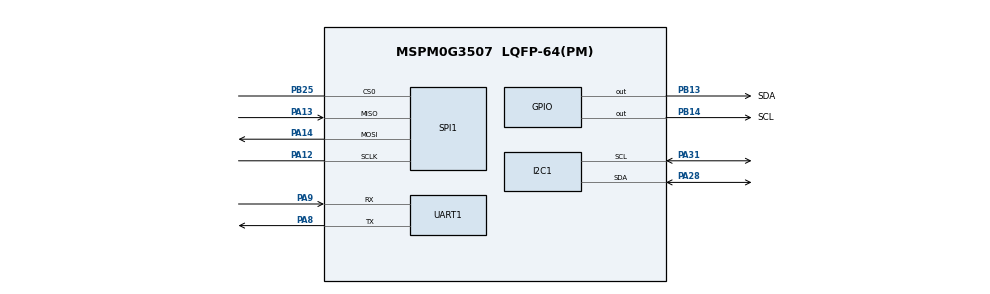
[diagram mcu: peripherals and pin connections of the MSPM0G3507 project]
/**
 * These arguments were used when this file was generated. They will be automatically applied on subsequent loads
 * via the GUI or CLI. Run CLI with '--help' for additional information on how to override these arguments.
 * @cliArgs --device "MSPM0G350X" --part "Default" --package "LQFP-64(PM)" --product "mspm0_sdk@2.11.00.07"
 * @v2CliArgs --device "MSPM0G3507" --package "LQFP-64(PM)" --product "mspm0_sdk@2.11.00.07"
 * @versions {"tool":"1.26.2+4477"}
 */

/**
 * Import the modules used in this configuration.
 */
const GPIO   = scripting.addModule("/ti/driverlib/GPIO", {}, false);
const GPIO1  = GPIO.addInstance();
const I2C    = scripting.addModule("/ti/driverlib/I2C", {}, false);
const I2C1   = I2C.addInstance();
const SPI    = scripting.addModule("/ti/driverlib/SPI", {}, false);
const SPI1   = SPI.addInstance();
const SYSCTL = scripting.addModule("/ti/driverlib/SYSCTL");
const TIMER  = scripting.addModule("/ti/driverlib/TIMER", {}, false);
const TIMER1 = TIMER.addInstance();
const UART   = scripting.addModule("/ti/driverlib/UART", {}, false);
const UART1  = UART.addInstance();

/**
 * Write custom configuration values to the imported modules.
 */
GPIO1.$name                         = "I2C_IMU";
GPIO1.associatedPins.create(2);
GPIO1.associatedPins[0].ioStructure = "SD";
GPIO1.associatedPins[0].$name       = "SCL";
GPIO1.associatedPins[0].pin.$assign = "PB14";
GPIO1.associatedPins[1].$name       = "SDA";
GPIO1.associatedPins[1].pin.$assign = "PB13";

const Board = scripting.addModule("/ti/driverlib/Board", {}, false);

I2C1.$name                             = "I2C_OLED";
I2C1.basicEnableController             = true;
I2C1.basicControllerStandardBusSpeed   = "Fast";
I2C1.peripheral.$assign                = "I2C0";
I2C1.peripheral.sdaPin.$assign         = "PA28";
I2C1.peripheral.sclPin.$assign         = "PA31";
I2C1.sdaPinConfig.$name                = "ti_driverlib_gpio_GPIOPinGeneric8";
I2C1.sdaPinConfig.hideOutputInversion  = scripting.forceWrite(false);
I2C1.sdaPinConfig.onlyInternalResistor = scripting.forceWrite(false);
I2C1.sdaPinConfig.passedPeripheralType = scripting.forceWrite("Digital");
I2C1.sclPinConfig.$name                = "ti_driverlib_gpio_GPIOPinGeneric9";
I2C1.sclPinConfig.hideOutputInversion  = scripting.forceWrite(false);
I2C1.sclPinConfig.onlyInternalResistor = scripting.forceWrite(false);
I2C1.sclPinConfig.passedPeripheralType = scripting.forceWrite("Digital");

SPI1.$name                              = "IMU";
SPI1.peripheral.$assign                 = "SPI0";
SPI1.peripheral.sclkPin.$assign         = "PA12";
SPI1.peripheral.mosiPin.$assign         = "PA14";
SPI1.peripheral.misoPin.$assign         = "PA13";
SPI1.peripheral.cs0Pin.$assign          = "PB25";
SPI1.sclkPinConfig.direction            = scripting.forceWrite("OUTPUT");
SPI1.sclkPinConfig.onlyInternalResistor = scripting.forceWrite(false);
SPI1.sclkPinConfig.passedPeripheralType = scripting.forceWrite("Digital");
SPI1.sclkPinConfig.$name                = "ti_driverlib_gpio_GPIOPinGeneric4";
SPI1.mosiPinConfig.direction            = scripting.forceWrite("OUTPUT");
SPI1.mosiPinConfig.hideOutputInversion  = scripting.forceWrite(false);
SPI1.mosiPinConfig.onlyInternalResistor = scripting.forceWrite(false);
SPI1.mosiPinConfig.passedPeripheralType = scripting.forceWrite("Digital");
SPI1.mosiPinConfig.$name                = "ti_driverlib_gpio_GPIOPinGeneric5";
SPI1.misoPinConfig.onlyInternalResistor = scripting.forceWrite(false);
SPI1.misoPinConfig.passedPeripheralType = scripting.forceWrite("Digital");
SPI1.misoPinConfig.$name                = "ti_driverlib_gpio_GPIOPinGeneric6";
SPI1.cs0PinConfig.direction             = scripting.forceWrite("OUTPUT");
SPI1.cs0PinConfig.hideOutputInversion   = scripting.forceWrite(false);
SPI1.cs0PinConfig.onlyInternalResistor  = scripting.forceWrite(false);
SPI1.cs0PinConfig.passedPeripheralType  = scripting.forceWrite("Digital");
SPI1.cs0PinConfig.$name                 = "ti_driverlib_gpio_GPIOPinGeneric7";

SYSCTL.forceDefaultClkConfig = true;

TIMER1.$name            = "TIMER_0";
TIMER1.timerClkPrescale = 32;
TIMER1.timerStartTimer  = true;
TIMER1.timerMode        = "PERIODIC_UP";

UART1.$name                            = "PIDHELPER";
UART1.targetBaudRate                   = 115200;
UART1.enabledInterrupts                = ["RX"];
UART1.peripheral.$assign               = "UART1";
UART1.peripheral.rxPin.$assign         = "PA9";
UART1.peripheral.txPin.$assign         = "PA8";
UART1.txPinConfig.direction            = scripting.forceWrite("OUTPUT");
UART1.txPinConfig.hideOutputInversion  = scripting.forceWrite(false);
UART1.txPinConfig.onlyInternalResistor = scripting.forceWrite(false);
UART1.txPinConfig.passedPeripheralType = scripting.forceWrite("Digital");
UART1.txPinConfig.$name                = "ti_driverlib_gpio_GPIOPinGeneric2";
UART1.rxPinConfig.hideOutputInversion  = scripting.forceWrite(false);
UART1.rxPinConfig.onlyInternalResistor = scripting.forceWrite(false);
UART1.rxPinConfig.passedPeripheralType = scripting.forceWrite("Digital");
UART1.rxPinConfig.$name                = "ti_driverlib_gpio_GPIOPinGeneric3";

/**
 * Pinmux solution for unlocked pins/peripherals. This ensures that minor changes to the automatic solver in a future
 * version of the tool will not impact the pinmux you originally saw.  These lines can be completely deleted in order to
 * re-solve from scratch.
 */
Board.peripheral.$suggestSolution          = "DEBUGSS";
Board.peripheral.swclkPin.$suggestSolution = "PA20";
Board.peripheral.swdioPin.$suggestSolution = "PA19";
SYSCTL.peripheral.$suggestSolution         = "SYSCTL";
TIMER1.peripheral.$suggestSolution         = "TIMA0";
